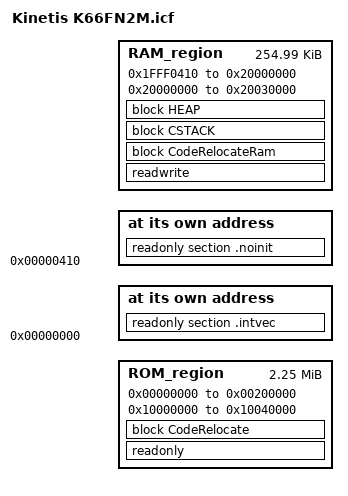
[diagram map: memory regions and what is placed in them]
/*###ICF### Section handled by ICF editor, don't touch! ****/
/*****************2017.1.6完成——by ALEX******************/
/*-Editor annotation file-*/
/* IcfEditorFile="$TOOLKIT_DIR$\config\ide\IcfEditor\cortex_v1_0.xml" */
/*-Specials-*/
define symbol __ICFEDIT_intvec_start__ = 0x00000000;
/*-Memory Regions-*/
define symbol __ICFEDIT_region_ROM_start__ = 0x00000000;
define symbol __ICFEDIT_region_ROM_end__   = 0x00200000;   ///////PFLASH 2M
define symbol __ICFEDIT_region_RAM_start__ = 0x1FFF0410;   //////SRAM_L
define symbol __ICFEDIT_region_RAM_end__   = 0x20000000;
/*-Sizes-*/
define symbol __ICFEDIT_size_cstack__ = 0x2000;    ///堆大小
define symbol __ICFEDIT_size_heap__   = 0x4000;     ///栈大小
/**** End of ICF editor section. ###ICF###*/

define symbol __region_FlexNVM_start__  = 0x10000000; /////FLEXNVM
define symbol __region_FlexNVM_end__    = 0x10040000;

define symbol __region_RAM2_start__ = 0x20000000;
define symbol __region_RAM2_end__ = 0x20030000;        //////SRAM_U  总计大小256K

define exported symbol __VECTOR_TABLE = __ICFEDIT_intvec_start__;
define exported symbol __VECTOR_RAM = __ICFEDIT_region_RAM_start__ - 0x410;//////中断向量表首址

define exported symbol __BOOT_STACK_ADDRESS = 0x2002FFF8;  //0x2002FFF8;       //启动栈地址

/* 决定代码编译的地址 */
define exported symbol __code_start__ = __ICFEDIT_intvec_start__ + 0x410;   //代码编译进 ROM ,则  __ICFEDIT_region_ROM_start__ + 0x410 ， RAM，则   __ICFEDIT_region_RAM_start__  + 0x410
                                                                                                               //+0x410 ,是前面的留给 Vector Table 
define memory mem with size = 4G;   //////4G寻址
define region ROM_region   = mem:[from __ICFEDIT_region_ROM_start__   to __ICFEDIT_region_ROM_end__] | mem:[from __region_FlexNVM_start__ to __region_FlexNVM_end__];//////ROM区域
define region RAM_region   = mem:[from __ICFEDIT_region_RAM_start__   to __ICFEDIT_region_RAM_end__] | mem:[from __region_RAM2_start__ to __region_RAM2_end__];    //////RAM区域

define block CSTACK    with alignment = 8, size = __ICFEDIT_size_cstack__   { };    //堆
define block HEAP      with alignment = 8, size = __ICFEDIT_size_heap__     { };    //栈


//手动初始化，在 common_startup函数 里完成
initialize manually { readwrite };             // 未初始化数据 .bss
initialize manually { section .data};          // 已初始化数据
initialize manually { section .textrw };       // __ramfunc声明的函数
do not initialize  { section .noinit };        // 复位中断向量服务函数

define block CodeRelocate { section .textrw_init };
define block CodeRelocateRam { section .textrw };         // CodeRelocateRam  把代码复制到RAM中(对flash操作的函数必须这样)

place at address mem:__ICFEDIT_intvec_start__ { readonly section .intvec };
place at address mem:__code_start__ { readonly section .noinit };

place in ROM_region   { readonly, block CodeRelocate};

place in RAM_region   { readwrite, block CodeRelocateRam,
                        block CSTACK, block HEAP };
 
